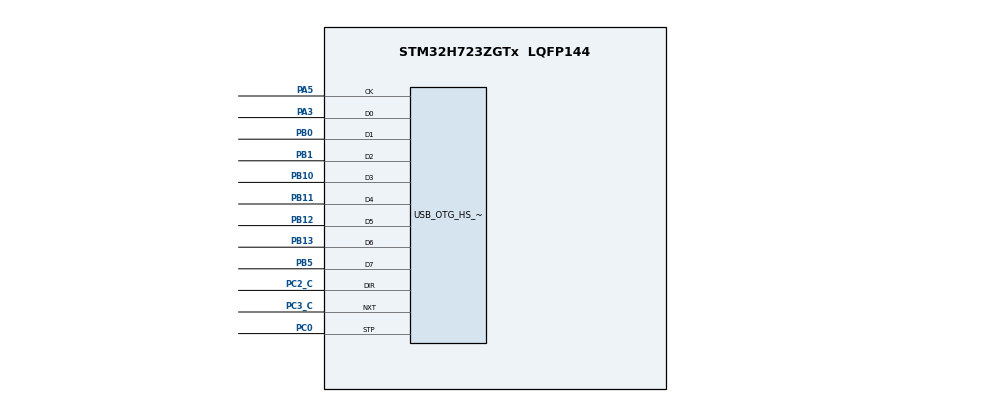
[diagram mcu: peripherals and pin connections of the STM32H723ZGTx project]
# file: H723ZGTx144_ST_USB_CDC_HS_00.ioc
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CORTEX_M7.default_mode_Activation=1
Mcu.Family=STM32H7
Mcu.Name=STM32H723ZGTx
Mcu.Package=LQFP144
NVIC.OTG_HS_IRQn=true\:0\:0\:false\:false\:true\:true\:true\:true
NVIC.PriorityGroup=NVIC_PRIORITYGROUP_4
NVIC.TIM6_DAC_IRQn=true\:15\:0\:false\:false\:true\:false\:true\:true
NVIC.TimeBase=TIM6_DAC_IRQn
NVIC.TimeBaseIP=TIM6
PA13(JTMS/SWDIO).Mode=Serial_Wire
PA13(JTMS/SWDIO).Signal=DEBUG_JTMS-SWDIO
PA14(JTCK/SWCLK).Mode=Serial_Wire
PA14(JTCK/SWCLK).Signal=DEBUG_JTCK-SWCLK
PA3.Mode=Device_HS
PA3.Signal=USB_OTG_HS_ULPI_D0
PA5.Mode=Device_HS
PA5.Signal=USB_OTG_HS_ULPI_CK
PB0.Mode=Device_HS
PB0.Signal=USB_OTG_HS_ULPI_D1
PB1.Mode=Device_HS
PB1.Signal=USB_OTG_HS_ULPI_D2
PB10.Mode=Device_HS
PB10.Signal=USB_OTG_HS_ULPI_D3
PB11.Mode=Device_HS
PB11.Signal=USB_OTG_HS_ULPI_D4
PB12.Mode=Device_HS
PB12.Signal=USB_OTG_HS_ULPI_D5
PB13.Mode=Device_HS
PB13.Signal=USB_OTG_HS_ULPI_D6
PB5.Mode=Device_HS
PB5.Signal=USB_OTG_HS_ULPI_D7
PC0.Mode=Device_HS
PC0.Signal=USB_OTG_HS_ULPI_STP
PC2_C.Mode=Device_HS
PC2_C.Signal=USB_OTG_HS_ULPI_DIR
PC3_C.Mode=Device_HS
PC3_C.Signal=USB_OTG_HS_ULPI_NXT
PH0-OSC_IN.Mode=HSE-External-Clock-Source
PH0-OSC_IN.Signal=RCC_OSC_IN
ProjectManager.HeapSize=0x200
ProjectManager.StackSize=0x400
ProjectManager.TargetToolchain=STM32CubeIDE
RCC.ADCFreq_Value=100781250
RCC.APB1Freq_Value=137500000
RCC.APB2Freq_Value=137500000
RCC.APB3Freq_Value=137500000
RCC.APB4Freq_Value=137500000
RCC.CortexFreq_Value=550000000
RCC.D1PPRE=RCC_APB3_DIV2
RCC.D2PPRE1=RCC_APB1_DIV2
RCC.D2PPRE2=RCC_APB2_DIV2
RCC.D3PPRE=RCC_APB4_DIV2
RCC.DIVM1=5
RCC.DIVN1=55
RCC.DIVP1=1
RCC.HCLKFreq_Value=275000000
RCC.HPRE=RCC_HCLK_DIV2
RCC.HSE_VALUE=50000000
RCC.PLLSourceVirtual=RCC_PLLSOURCE_HSE
RCC.RCC_TIM_PRescaler_Selection=RCC_TIMPRES_DESACTIVATED
RCC.SYSCLKFreq_VALUE=550000000
RCC.SYSCLKSource=RCC_SYSCLKSOURCE_PLLCLK
RCC.USBCLockSelection=RCC_USBCLKSOURCE_HSI48
RCC.USBFreq_Value=48000000
USB_DEVICE.CLASS_NAME_HS=CDC
USB_DEVICE.VirtualMode=Cdc
USB_DEVICE.VirtualModeHS=Cdc_HS
USB_OTG_HS.VirtualMode-Device_HS=Device_HS
USB_OTG_HS.dma_enable-Device_HS=ENABLE
VP_MEMORYMAP_VS_MEMORYMAP.Mode=CurAppReg
VP_SYS_VS_tim6.Mode=TIM6
VP_USB_DEVICE_VS_USB_DEVICE_CDC_HS.Mode=CDC_HS
board=custom

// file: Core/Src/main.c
/* USER CODE BEGIN Header */
/**
  ******************************************************************************
  * @file           : main.c
  * @brief          : Main program body
  ******************************************************************************
  * @attention
  *
  * Copyright (c) 2025 STMicroelectronics.
  * All rights reserved.
  *
  * This software is licensed under terms that can be found in the LICENSE file
  * in the root directory of this software component.
  * If no LICENSE file comes with this software, it is provided AS-IS.
  *
  ******************************************************************************
  */
/* USER CODE END Header */
#include "main.h"
#include "usb_device.h"
#include "gpio.h"

/* USER CODE BEGIN Includes */
#include "usbd_cdc_if.h"
/* USER CODE END Includes */

void SystemClock_Config(void);
static void MPU_Config(void);

int main(void)
{

  /* MPU Configuration--------------------------------------------------------*/
  MPU_Config();

  /* MCU Configuration--------------------------------------------------------*/

  /* Reset of all peripherals, Initializes the Flash interface and the Systick. */
  HAL_Init();

  /* Configure the system clock */
  SystemClock_Config();

  /* Initialize all configured peripherals */
  MX_GPIO_Init();
  MX_USB_DEVICE_Init();

  /* Infinite loop */
  /* USER CODE BEGIN WHILE */
  while (1)
  {
      HAL_Delay(500);
      char* buf = "Hello World!\r\n";
      CDC_Transmit_HS((uint8_t*)buf, 30);
    /* USER CODE END WHILE */

  }
}

void SystemClock_Config(void)
{
  RCC_OscInitTypeDef RCC_OscInitStruct = {0};
  RCC_ClkInitTypeDef RCC_ClkInitStruct = {0};

  /** Supply configuration update enable
  */
  HAL_PWREx_ConfigSupply(PWR_LDO_SUPPLY);

  /** Configure the main internal regulator output voltage
  */
  __HAL_PWR_VOLTAGESCALING_CONFIG(PWR_REGULATOR_VOLTAGE_SCALE0);

  while(!__HAL_PWR_GET_FLAG(PWR_FLAG_VOSRDY)) {}

  /** Initializes the RCC Oscillators according to the specified parameters
  * in the RCC_OscInitTypeDef structure.
  */
  RCC_OscInitStruct.OscillatorType = RCC_OSCILLATORTYPE_HSI48|RCC_OSCILLATORTYPE_HSE;
  RCC_OscInitStruct.HSEState = RCC_HSE_BYPASS;
  RCC_OscInitStruct.HSI48State = RCC_HSI48_ON;
  RCC_OscInitStruct.PLL.PLLState = RCC_PLL_ON;
  RCC_OscInitStruct.PLL.PLLSource = RCC_PLLSOURCE_HSE;
  RCC_OscInitStruct.PLL.PLLM = 5;
  RCC_OscInitStruct.PLL.PLLN = 55;
  RCC_OscInitStruct.PLL.PLLP = 1;
  RCC_OscInitStruct.PLL.PLLQ = 2;
  RCC_OscInitStruct.PLL.PLLR = 2;
  RCC_OscInitStruct.PLL.PLLRGE = RCC_PLL1VCIRANGE_3;
  RCC_OscInitStruct.PLL.PLLVCOSEL = RCC_PLL1VCOWIDE;
  RCC_OscInitStruct.PLL.PLLFRACN = 0;
  if (HAL_RCC_OscConfig(&RCC_OscInitStruct) != HAL_OK)
  {
    Error_Handler();
  }

  /** Initializes the CPU, AHB and APB buses clocks
  */
  RCC_ClkInitStruct.ClockType = RCC_CLOCKTYPE_HCLK|RCC_CLOCKTYPE_SYSCLK
                              |RCC_CLOCKTYPE_PCLK1|RCC_CLOCKTYPE_PCLK2
                              |RCC_CLOCKTYPE_D3PCLK1|RCC_CLOCKTYPE_D1PCLK1;
  RCC_ClkInitStruct.SYSCLKSource = RCC_SYSCLKSOURCE_PLLCLK;
  RCC_ClkInitStruct.SYSCLKDivider = RCC_SYSCLK_DIV1;
  RCC_ClkInitStruct.AHBCLKDivider = RCC_HCLK_DIV2;
  RCC_ClkInitStruct.APB3CLKDivider = RCC_APB3_DIV2;
  RCC_ClkInitStruct.APB1CLKDivider = RCC_APB1_DIV2;
  RCC_ClkInitStruct.APB2CLKDivider = RCC_APB2_DIV2;
  RCC_ClkInitStruct.APB4CLKDivider = RCC_APB4_DIV2;

  if (HAL_RCC_ClockConfig(&RCC_ClkInitStruct, FLASH_LATENCY_3) != HAL_OK)
  {
    Error_Handler();
  }
}

 /* MPU Configuration */

void MPU_Config(void)
{
  MPU_Region_InitTypeDef MPU_InitStruct = {0};

  /* Disables the MPU */
  HAL_MPU_Disable();

  /** Initializes and configures the Region and the memory to be protected
  */
  MPU_InitStruct.Enable = MPU_REGION_ENABLE;
  MPU_InitStruct.Number = MPU_REGION_NUMBER0;
  MPU_InitStruct.BaseAddress = 0x0;
  MPU_InitStruct.Size = MPU_REGION_SIZE_4GB;
  MPU_InitStruct.SubRegionDisable = 0x87;
  MPU_InitStruct.TypeExtField = MPU_TEX_LEVEL0;
  MPU_InitStruct.AccessPermission = MPU_REGION_NO_ACCESS;
  MPU_InitStruct.DisableExec = MPU_INSTRUCTION_ACCESS_DISABLE;
  MPU_InitStruct.IsShareable = MPU_ACCESS_SHAREABLE;
  MPU_InitStruct.IsCacheable = MPU_ACCESS_NOT_CACHEABLE;
  MPU_InitStruct.IsBufferable = MPU_ACCESS_NOT_BUFFERABLE;

  HAL_MPU_ConfigRegion(&MPU_InitStruct);
  /* Enables the MPU */
  HAL_MPU_Enable(MPU_PRIVILEGED_DEFAULT);

}

void HAL_TIM_PeriodElapsedCallback(TIM_HandleTypeDef *htim)
{
  if (htim->Instance == TIM6)
  {
    HAL_IncTick();
  }
}

void Error_Handler(void)
{
  __disable_irq();
  while (1)
  {
  }
}
